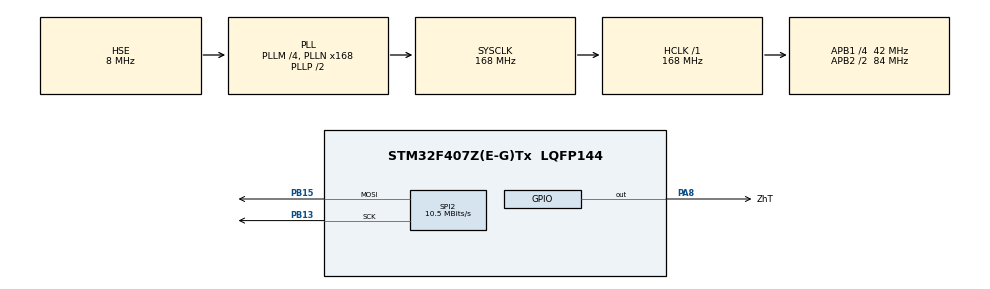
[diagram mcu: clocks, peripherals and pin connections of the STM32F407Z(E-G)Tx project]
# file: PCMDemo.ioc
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Mcu.Family=STM32F4
Mcu.Name=STM32F407Z(E-G)Tx
Mcu.Package=LQFP144
NVIC.PriorityGroup=NVIC_PRIORITYGROUP_4
PA13.Mode=Serial_Wire
PA13.Signal=SYS_JTMS-SWDIO
PA14.Mode=Serial_Wire
PA14.Signal=SYS_JTCK-SWCLK
PA8.GPIO_Label=ZhT
PA8.GPIO_PuPd=GPIO_PULLUP
PA8.GPIO_Speed=GPIO_SPEED_FREQ_HIGH
PA8.PinState=GPIO_PIN_SET
PA8.Signal=GPIO_Output
PB13.Mode=TX_Only_Simplex_Unidirect_Master
PB13.Signal=SPI2_SCK
PB15.Mode=TX_Only_Simplex_Unidirect_Master
PB15.Signal=SPI2_MOSI
PH0-OSC_IN.Mode=HSE-External-Oscillator
PH0-OSC_IN.Signal=RCC_OSC_IN
PH1-OSC_OUT.Mode=HSE-External-Oscillator
PH1-OSC_OUT.Signal=RCC_OSC_OUT
ProjectManager.HeapSize=0x200
ProjectManager.StackSize=0x400
ProjectManager.TargetToolchain=Other Toolchains (GPDSC)
RCC.48MHZClocksFreq_Value=84000000
RCC.AHBFreq_Value=168000000
RCC.APB1CLKDivider=RCC_HCLK_DIV4
RCC.APB1Freq_Value=42000000
RCC.APB1TimFreq_Value=84000000
RCC.APB2CLKDivider=RCC_HCLK_DIV2
RCC.APB2Freq_Value=84000000
RCC.APB2TimFreq_Value=168000000
RCC.CortexFreq_Value=168000000
RCC.HCLKFreq_Value=168000000
RCC.HSE_VALUE=8000000
RCC.HSI_VALUE=16000000
RCC.LSE_VALUE=32768
RCC.PLLM=4
RCC.PLLN=168
RCC.PLLSourceVirtual=RCC_PLLSOURCE_HSE
RCC.SYSCLKFreq_VALUE=168000000
RCC.SYSCLKSource=RCC_SYSCLKSOURCE_PLLCLK
RCC.VCOOutputFreq_Value=336000000
SPI2.BaudRatePrescaler=SPI_BAUDRATEPRESCALER_4
SPI2.CLKPhase=SPI_PHASE_1EDGE
SPI2.CLKPolarity=SPI_POLARITY_HIGH
SPI2.CalculateBaudRate=10.5 MBits/s
SPI2.Direction=SPI_DIRECTION_2LINES
SPI2.Mode=SPI_MODE_MASTER
SPI2.VirtualType=VM_MASTER
board=custom

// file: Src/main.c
/**
  ******************************************************************************
  * @file           : main.c
  * @brief          : Main program body
  ******************************************************************************
  ** This notice applies to any and all portions of this file
  * that are not between comment pairs USER CODE BEGIN and
  * USER CODE END. Other portions of this file, whether
  * inserted by the user or by software development tools
  * are owned by their respective copyright owners.
  *
  * COPYRIGHT(c) 2018 STMicroelectronics
  *
  * Redistribution and use in source and binary forms, with or without modification,
  * are permitted provided that the following conditions are met:
  *   1. Redistributions of source code must retain the above copyright notice,
  *      this list of conditions and the following disclaimer.
  *   2. Redistributions in binary form must reproduce the above copyright notice,
  *      this list of conditions and the following disclaimer in the documentation
  *      and/or other materials provided with the distribution.
  *   3. Neither the name of STMicroelectronics nor the names of its contributors
  *      may be used to endorse or promote products derived from this software
  *      without specific prior written permission.
  *
  * THIS SOFTWARE IS PROVIDED BY THE COPYRIGHT HOLDERS AND CONTRIBUTORS "AS IS"
  * AND ANY EXPRESS OR IMPLIED WARRANTIES, INCLUDING, BUT NOT LIMITED TO, THE
  * IMPLIED WARRANTIES OF MERCHANTABILITY AND FITNESS FOR A PARTICULAR PURPOSE ARE
  * DISCLAIMED. IN NO EVENT SHALL THE COPYRIGHT HOLDER OR CONTRIBUTORS BE LIABLE
  * FOR ANY DIRECT, INDIRECT, INCIDENTAL, SPECIAL, EXEMPLARY, OR CONSEQUENTIAL
  * DAMAGES (INCLUDING, BUT NOT LIMITED TO, PROCUREMENT OF SUBSTITUTE GOODS OR
  * SERVICES; LOSS OF USE, DATA, OR PROFITS; OR BUSINESS INTERRUPTION) HOWEVER
  * CAUSED AND ON ANY THEORY OF LIABILITY, WHETHER IN CONTRACT, STRICT LIABILITY,
  * OR TORT (INCLUDING NEGLIGENCE OR OTHERWISE) ARISING IN ANY WAY OUT OF THE USE
  * OF THIS SOFTWARE, EVEN IF ADVISED OF THE POSSIBILITY OF SUCH DAMAGE.
  *
  ******************************************************************************
  */
#include "main.h"
#include "stm32f4xx_hal.h"
#include "spi.h"
#include "gpio.h"

/* USER CODE BEGIN PV */
/* Private variables ---------------------------------------------------------*/

/* USER CODE END PV */

void SystemClock_Config(void);

/* USER CODE BEGIN PFP */
/* Private function prototypes -----------------------------------------------*/

/* USER CODE END PFP */

int main(void)
{
  /* USER CODE BEGIN 1 */
	uint8_t i,x,tx[250],index,ddi;
  /* USER CODE END 1 */

  /* MCU Configuration----------------------------------------------------------*/

  /* Reset of all peripherals, Initializes the Flash interface and the Systick. */
  HAL_Init();

  /* Configure the system clock */
  SystemClock_Config();

  /* Initialize all configured peripherals */
  MX_GPIO_Init();
  MX_SPI2_Init();

  /* Infinite loop */
  /* USER CODE BEGIN WHILE */
  x=0;
  index=0;
  tx[0]=0xfa;
  tx[1]=0xf3;
  tx[2]=0x30;
  //tx[3]=0xfa;
  while (1)
  {
	  index++;
	  x++;
	  tx[3]=0xe0;
	  tx[4]=index;
	  tx[5]=0x00;
	  tx[6]=3*12+3*8;
	  for(i=0;i<12;i++)
	  {
		  tx[7+i*3]=0xa0+i;
		  tx[7+i*3+1]=x;
		  tx[7+i*3+2]=x;
	  }
	  for(i=0;i<8;i++)
	  {
		  tx[7+36+i*3]=0xc0+i;
		  tx[7+36+i*3+1]=x;
		  tx[7+36+i*3+2]=x;
	  }
	  HAL_GPIO_WritePin(ZhT_GPIO_Port,ZhT_Pin,GPIO_PIN_RESET);
	  HAL_Delay(1);
	  HAL_SPI_Transmit(&hspi2,tx,7+36+24,1000);
	  HAL_Delay(1);
	  HAL_GPIO_WritePin(ZhT_GPIO_Port,ZhT_Pin,GPIO_PIN_SET);
	  HAL_Delay(100);

	  tx[3]=0xe1;
	  tx[4]=index;
	  tx[5]=0x00;
	  tx[6]=140;
	  ddi=7;
	  tx[ddi++]=0xb8;
	  for(i=0;i<8;i++)
	  {
		  tx[ddi++]=x;
	  }
	  tx[ddi++]=0xb9;
	  for(i=0;i<8;i++)
	  {
		  tx[ddi++]=x;
	  }
	  tx[ddi++]=0xba;
	  for(i=0;i<8;i++)
	  {
		  tx[ddi++]=x;
	  }
	  tx[ddi++]=0xbb;
	  for(i=0;i<8;i++)
	  {
		  tx[ddi++]=x;
	  }

	  tx[ddi++]=0xbc;
	  for(i=0;i<7;i++)
	  {
		  tx[ddi++]=x;
	  }
	  tx[ddi++]=0xbd;
	  for(i=0;i<7;i++)
	  {
		  tx[ddi++]=x;
	  }
	  tx[ddi++]=0xbe;
	  for(i=0;i<7;i++)
	  {
		  tx[ddi++]=x;
	  }
	  tx[ddi++]=0xbf;
	  for(i=0;i<7;i++)
	  {
		  tx[ddi++]=x;
	  }

	  tx[ddi++]=0xc0;
	  for(i=0;i<4;i++)
	  {
		  tx[ddi++]=x;
	  }
	  tx[ddi++]=0xc1;
	  for(i=0;i<4;i++)
	  {
		  tx[ddi++]=x;
	  }
	  tx[ddi++]=0xc2;
	  for(i=0;i<4;i++)
	  {
		  tx[ddi++]=x;
	  }
	  tx[ddi++]=0xc3;
	  for(i=0;i<4;i++)
	  {
		  tx[ddi++]=x;
	  }

	  tx[ddi++]=0xc4;
	  for(i=0;i<1;i++)
	  {
		  tx[ddi++]=x;
	  }
	  tx[ddi++]=0xc5;
	  for(i=0;i<1;i++)
	  {
		  tx[ddi++]=x;
	  }
	  tx[ddi++]=0xc6;
	  for(i=0;i<1;i++)
	  {
		  tx[ddi++]=x;
	  }
	  tx[ddi++]=0xc7;
	  for(i=0;i<1;i++)
	  {
		  tx[ddi++]=x;
	  }

	  tx[ddi++]=0xc8;
	  for(i=0;i<8;i++)
	  {
		  tx[ddi++]=x;
	  }
	  tx[ddi++]=0xc9;
	  for(i=0;i<8;i++)
	  {
		  tx[ddi++]=x;
	  }
	  tx[ddi++]=0xca;
	  for(i=0;i<9;i++)
	  {
		  tx[ddi++]=x;
	  }
	  tx[ddi++]=0xcb;
	  for(i=0;i<9;i++)
	  {
		  tx[ddi++]=x;
	  }

	  tx[ddi++]=0xcc;
	  for(i=0;i<2;i++)
	  {
		  tx[ddi++]=x;
	  }
	  tx[ddi++]=0xcd;
	  for(i=0;i<2;i++)
	  {
		  tx[ddi++]=x;
	  }
	  HAL_GPIO_WritePin(ZhT_GPIO_Port,ZhT_Pin,GPIO_PIN_RESET);
	  HAL_Delay(1);
	  HAL_SPI_Transmit(&hspi2,tx,7+140,1000);
	  HAL_Delay(1);
	  HAL_GPIO_WritePin(ZhT_GPIO_Port,ZhT_Pin,GPIO_PIN_SET);
	  HAL_Delay(100);
  /* USER CODE END WHILE */

  }

}

void SystemClock_Config(void)
{

  RCC_OscInitTypeDef RCC_OscInitStruct;
  RCC_ClkInitTypeDef RCC_ClkInitStruct;

    /**Configure the main internal regulator output voltage
    */
  __HAL_RCC_PWR_CLK_ENABLE();

  __HAL_PWR_VOLTAGESCALING_CONFIG(PWR_REGULATOR_VOLTAGE_SCALE1);

    /**Initializes the CPU, AHB and APB busses clocks
    */
  RCC_OscInitStruct.OscillatorType = RCC_OSCILLATORTYPE_HSE;
  RCC_OscInitStruct.HSEState = RCC_HSE_ON;
  RCC_OscInitStruct.PLL.PLLState = RCC_PLL_ON;
  RCC_OscInitStruct.PLL.PLLSource = RCC_PLLSOURCE_HSE;
  RCC_OscInitStruct.PLL.PLLM = 4;
  RCC_OscInitStruct.PLL.PLLN = 168;
  RCC_OscInitStruct.PLL.PLLP = RCC_PLLP_DIV2;
  RCC_OscInitStruct.PLL.PLLQ = 4;
  if (HAL_RCC_OscConfig(&RCC_OscInitStruct) != HAL_OK)
  {
    _Error_Handler(__FILE__, __LINE__);
  }

    /**Initializes the CPU, AHB and APB busses clocks
    */
  RCC_ClkInitStruct.ClockType = RCC_CLOCKTYPE_HCLK|RCC_CLOCKTYPE_SYSCLK
                              |RCC_CLOCKTYPE_PCLK1|RCC_CLOCKTYPE_PCLK2;
  RCC_ClkInitStruct.SYSCLKSource = RCC_SYSCLKSOURCE_PLLCLK;
  RCC_ClkInitStruct.AHBCLKDivider = RCC_SYSCLK_DIV1;
  RCC_ClkInitStruct.APB1CLKDivider = RCC_HCLK_DIV4;
  RCC_ClkInitStruct.APB2CLKDivider = RCC_HCLK_DIV2;

  if (HAL_RCC_ClockConfig(&RCC_ClkInitStruct, FLASH_LATENCY_5) != HAL_OK)
  {
    _Error_Handler(__FILE__, __LINE__);
  }

    /**Configure the Systick interrupt time
    */
  HAL_SYSTICK_Config(HAL_RCC_GetHCLKFreq()/1000);

    /**Configure the Systick
    */
  HAL_SYSTICK_CLKSourceConfig(SYSTICK_CLKSOURCE_HCLK);

  /* SysTick_IRQn interrupt configuration */
  HAL_NVIC_SetPriority(SysTick_IRQn, 0, 0);
}

void _Error_Handler(char *file, int line)
{
  while(1)
  {
  }
}

/************************ (C) COPYRIGHT STMicroelectronics *****END OF FILE****/
